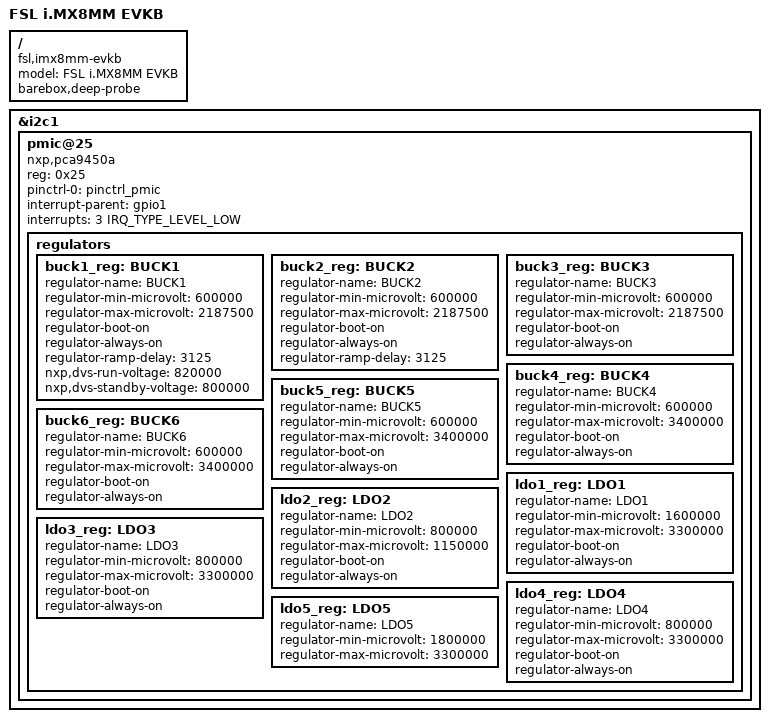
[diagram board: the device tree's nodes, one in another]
// SPDX-License-Identifier: (GPL-2.0 OR MIT)
/*
 * Copyright 2017 NXP
 * Copyright (C) 2017 Pengutronix, Lucas Stach <kernel@pengutronix.de>
 * Copyright (C) 2023 Pengutronix, Marco Felsch <kernel@pengutronix.de>
 */

/dts-v1/;

#include <arm64/freescale/imx8mm-evk.dts>
#include "imx8mm.dtsi"
#include "imx8mm-evk.dtsi"

/ {
	model = "FSL i.MX8MM EVKB";
	compatible = "fsl,imx8mm-evkb", "fsl,imx8mm";
	barebox,deep-probe;
};

&i2c1 {
	/delete-node/ pmic@4b;

	pmic@25 {
		compatible = "nxp,pca9450a";
		reg = <0x25>;
		pinctrl-0 = <&pinctrl_pmic>;
		pinctrl-names = "default";
		interrupt-parent = <&gpio1>;
		interrupts = <3 IRQ_TYPE_LEVEL_LOW>;

		regulators {
			buck1_reg: BUCK1 {
				regulator-name = "BUCK1";
				regulator-min-microvolt = <600000>;
				regulator-max-microvolt = <2187500>;
				regulator-boot-on;
				regulator-always-on;
				regulator-ramp-delay = <3125>;
				nxp,dvs-run-voltage = <820000>;
				nxp,dvs-standby-voltage = <800000>;
			};

			buck2_reg: BUCK2 {
				regulator-name = "BUCK2";
				regulator-min-microvolt = <600000>;
				regulator-max-microvolt = <2187500>;
				regulator-boot-on;
				regulator-always-on;
				regulator-ramp-delay = <3125>;
			};

			buck3_reg: BUCK3 {
				regulator-name = "BUCK3";
				regulator-min-microvolt = <600000>;
				regulator-max-microvolt = <2187500>;
				regulator-boot-on;
				regulator-always-on;
			};

			buck4_reg: BUCK4 {
				regulator-name = "BUCK4";
				regulator-min-microvolt = <600000>;
				regulator-max-microvolt = <3400000>;
				regulator-boot-on;
				regulator-always-on;
			};

			buck5_reg: BUCK5 {
				regulator-name = "BUCK5";
				regulator-min-microvolt = <600000>;
				regulator-max-microvolt = <3400000>;
				regulator-boot-on;
				regulator-always-on;
			};

			buck6_reg: BUCK6 {
				regulator-name = "BUCK6";
				regulator-min-microvolt = <600000>;
				regulator-max-microvolt = <3400000>;
				regulator-boot-on;
				regulator-always-on;
			};

			ldo1_reg: LDO1 {
				regulator-name = "LDO1";
				regulator-min-microvolt = <1600000>;
				regulator-max-microvolt = <3300000>;
				regulator-boot-on;
				regulator-always-on;
			};

			ldo2_reg: LDO2 {
				regulator-name = "LDO2";
				regulator-min-microvolt = <800000>;
				regulator-max-microvolt = <1150000>;
				regulator-boot-on;
				regulator-always-on;
			};

			ldo3_reg: LDO3 {
				regulator-name = "LDO3";
				regulator-min-microvolt = <800000>;
				regulator-max-microvolt = <3300000>;
				regulator-boot-on;
				regulator-always-on;
			};

			ldo4_reg: LDO4 {
				regulator-name = "LDO4";
				regulator-min-microvolt = <800000>;
				regulator-max-microvolt = <3300000>;
				regulator-boot-on;
				regulator-always-on;
			};

			ldo5_reg: LDO5 {
				regulator-name = "LDO5";
				regulator-min-microvolt = <1800000>;
				regulator-max-microvolt = <3300000>;
			};
		};
	};
};
